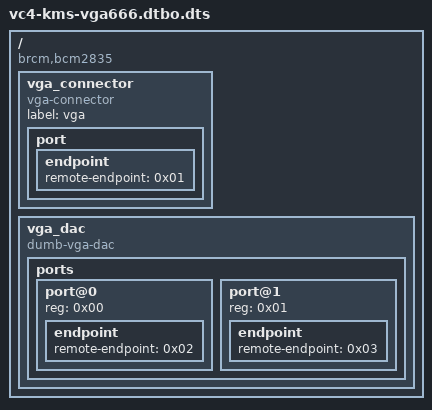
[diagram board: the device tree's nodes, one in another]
/dts-v1/;

/ {
	compatible = "brcm,bcm2835";

	fragment@0 {
		target-path = "/";

		__overlay__ {

			vga_connector {
				compatible = "vga-connector";
				label = "vga";
				phandle = <0x05>;

				port {

					endpoint {
						remote-endpoint = <0x01>;
						phandle = <0x03>;
					};
				};
			};

			vga_dac {
				compatible = "dumb-vga-dac";

				ports {
					#address-cells = <0x01>;
					#size-cells = <0x00>;

					port@0 {
						reg = <0x00>;

						endpoint {
							remote-endpoint = <0x02>;
							phandle = <0x04>;
						};
					};

					port@1 {
						reg = <0x01>;

						endpoint {
							remote-endpoint = <0x03>;
							phandle = <0x01>;
						};
					};
				};
			};
		};
	};

	fragment@1 {
		target = <0xffffffff>;

		__overlay__ {
			status = "okay";
			pinctrl-names = "default";
			pinctrl-0 = <0xffffffff>;

			port {

				endpoint@0 {
					remote-endpoint = <0x04>;
					phandle = <0x02>;
				};
			};
		};
	};

	fragment@2 {
		target = <0x05>;

		__dormant__ {
			ddc-i2c-bus = <0xffffffff>;
		};
	};

	fragment@3 {
		target = <0xffffffff>;

		__dormant__ {
			status = "okay";
		};
	};

	fragment@4 {
		target = <0xffffffff>;

		__dormant__ {
			status = "okay";
		};
	};

	__overrides__ {
		ddc = [00 00 00 00 3d 32 00 00 00 00 00 3d 33 00 00 00 00 00 3d 34 00];
	};

	__symbols__ {
		vga_connector = "/fragment@0/__overlay__/vga_connector";
		vga_con_in = "/fragment@0/__overlay__/vga_connector/port/endpoint";
		vga666_in = "/fragment@0/__overlay__/vga_dac/ports/port@0/endpoint";
		vga666_out = "/fragment@0/__overlay__/vga_dac/ports/port@1/endpoint";
		dpi_out = "/fragment@1/__overlay__/port/endpoint@0";
	};

	__fixups__ {
		dpi = "/fragment@1:target:0";
		dpi_18bit_gpio2 = "/fragment@1/__overlay__:pinctrl-0:0";
		i2c_vc = "/fragment@2/__dormant__:ddc-i2c-bus:0";
		i2c0if = "/fragment@3:target:0";
		i2c0mux = "/fragment@4:target:0";
	};

	__local_fixups__ {

		fragment@0 {

			__overlay__ {

				vga_connector {

					port {

						endpoint {
							remote-endpoint = <0x00>;
						};
					};
				};

				vga_dac {

					ports {

						port@0 {

							endpoint {
								remote-endpoint = <0x00>;
							};
						};

						port@1 {

							endpoint {
								remote-endpoint = <0x00>;
							};
						};
					};
				};
			};
		};

		fragment@1 {

			__overlay__ {

				port {

					endpoint@0 {
						remote-endpoint = <0x00>;
					};
				};
			};
		};

		fragment@2 {
			target = <0x00>;
		};
	};
};
